# CTRL_MODULE_CORE_PAD register map
Vendor: Texas Instruments
Registers are 32-bit, access per field, reset 0x10F010F unless marked. A register's access mark holds for its fields unless they carry their own. Offsets are as the file gives them; [hi:lo] are bit positions; 'fields as' and 'values as' point back to an identical list.

## CTRL_MODULE_CORE_PAD (part 5 of 7)
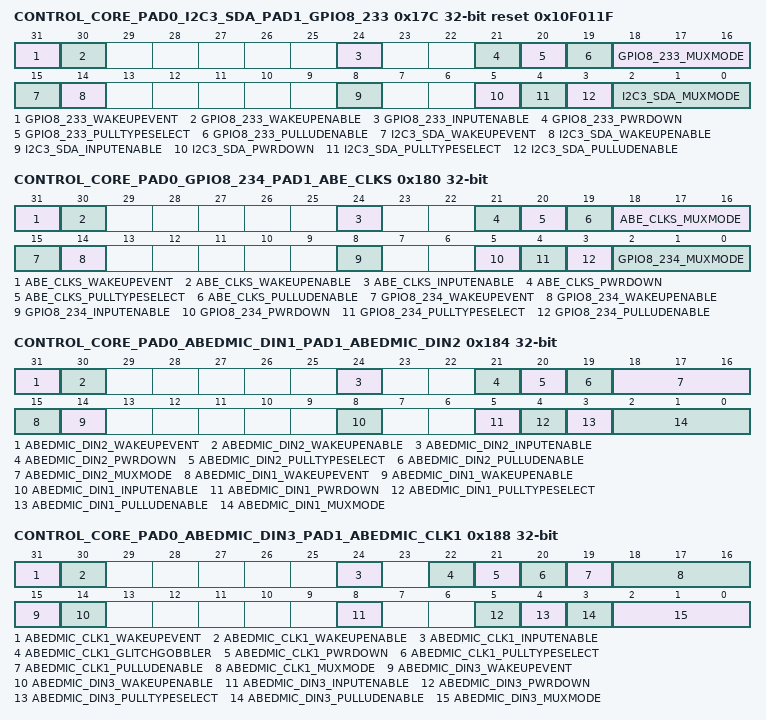
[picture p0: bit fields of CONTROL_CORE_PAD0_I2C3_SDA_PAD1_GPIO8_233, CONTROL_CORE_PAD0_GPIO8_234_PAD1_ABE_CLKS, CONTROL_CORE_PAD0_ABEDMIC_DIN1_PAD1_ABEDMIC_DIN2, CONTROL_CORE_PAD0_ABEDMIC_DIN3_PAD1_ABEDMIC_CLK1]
0x17C CONTROL_CORE_PAD0_I2C3_SDA_PAD1_GPIO8_233 reset 0x10F011F — Register control for Pads i2c3_sda and gpio8_233 Access conditions. Read: unrestricted, Write: unrestricted
  [31] GPIO8_233_WAKEUPEVENT ro — Pad_x wake-up event status latched in the IO
    1=WakeUp (A wake-up event occurred); 0=No wake-up event occurred
  [30] GPIO8_233_WAKEUPENABLE rw — Input pad wake-up enable
    0=DetectLow (wake-up detection is disabled); 1=DetectLowHigh (wake-up detection is enabled)
  [24] GPIO8_233_INPUTENABLE rw — Input enable value for pad gpio8_233
    0=InputBufferDisabled (Input buffer of IO cell is disabled); 1=InputBufferEnabled (Input buffer of IO cell is enabled)
  [21] GPIO8_233_PWRDOWN rw — Power Down setting for pad gpio8_233
    0=PwrDownDisabled (IO cell power is ON); 1=PwrDownEnabled (IO cell power is OFF)
  [20] GPIO8_233_PULLTYPESELECT rw — Pull-Up/Down selection for pad gpio8_233
    0=Pull-Down selected; 1=Pull-Up selected
  [19] GPIO8_233_PULLUDENABLE rw — Pull-Up/Down enable for pad gpio8_233
    0=PullDisabled (Pull-Up/Down disabled); 1=PullEnabled (Pull-Up/Down enabled)
  [18:16] GPIO8_233_MUXMODE rw — Functional multiplexing selection for pad gpio8_233
    6=SEL_GPIO8_233_1 (Select gpio8_233); 1=SEL_SYS_SECURE_INDICATOR (Reserved); 7=SEL_SAFE_MODE_CORE139 (Select safe_mode_core139); 0=SEL_GPIO8_233 (Select gpio8_233); 2=SEL_TIMER8_PWM_EVT (Select timer8_pwm_evt); 3=SEL_CPI_HSYNC (Select cpi_hsync)
  [15] I2C3_SDA_WAKEUPEVENT ro — Pad_x wake-up event status latched in the IO
    values as GPIO8_233_WAKEUPEVENT
  [14] I2C3_SDA_WAKEUPENABLE rw — Input pad wake-up enable
    values as GPIO8_233_WAKEUPENABLE
  [8] I2C3_SDA_INPUTENABLE rw — Input enable value for pad i2c3_sda
    values as GPIO8_233_INPUTENABLE
  [5] I2C3_SDA_PWRDOWN rw — Power Down setting for pad i2c3_sda
    values as GPIO8_233_PWRDOWN
  [4] I2C3_SDA_PULLTYPESELECT rw — Pull-Up/Down selection for pad i2c3_sda
    0=Pull-Down selected; 1=Pull-Up selected
  [3] I2C3_SDA_PULLUDENABLE rw — Pull-Up/Down enable for pad i2c3_sda
    values as GPIO8_233_PULLUDENABLE
  [2:0] I2C3_SDA_MUXMODE rw — Functional multiplexing selection for pad i2c3_sda
    0=SEL_I2C3_SDA (Select i2c3_sda); 7=SEL_SAFE_MODE_CORE138 (Select safe_mode_core138); 6=SEL_GPIO8_232 (Select gpio8_232)
0x180 CONTROL_CORE_PAD0_GPIO8_234_PAD1_ABE_CLKS — Register control for Pads gpio8_234 and abe_clks Access conditions. Read: unrestricted, Write: unrestricted
  [31] ABE_CLKS_WAKEUPEVENT ro — Pad_x wake-up event status latched in the IO
    values as CONTROL_CORE_PAD0_I2C3_SDA_PAD1_GPIO8_233.GPIO8_233_WAKEUPEVENT
  [30] ABE_CLKS_WAKEUPENABLE rw — Input pad wake-up enable
    values as CONTROL_CORE_PAD0_I2C3_SDA_PAD1_GPIO8_233.GPIO8_233_WAKEUPENABLE
  [24] ABE_CLKS_INPUTENABLE rw — Input enable value for pad abe_clks
    values as CONTROL_CORE_PAD0_I2C3_SDA_PAD1_GPIO8_233.GPIO8_233_INPUTENABLE
  [21] ABE_CLKS_PWRDOWN rw — Power Down setting for pad abe_clks
    values as CONTROL_CORE_PAD0_I2C3_SDA_PAD1_GPIO8_233.GPIO8_233_PWRDOWN
  [20] ABE_CLKS_PULLTYPESELECT rw — Pull-Up/Down selection for pad abe_clks
    0=Pull-Down selected; 1=Pull-Up selected
  [19] ABE_CLKS_PULLUDENABLE rw — Pull-Up/Down enable for pad abe_clks
    values as CONTROL_CORE_PAD0_I2C3_SDA_PAD1_GPIO8_233.GPIO8_233_PULLUDENABLE
  [18:16] ABE_CLKS_MUXMODE rw — Functional multiplexing selection for pad abe_clks
    0=SEL_ABE_CLKS (Select abe_clks); 3=SEL_ABEMCASP_AXR (Select abemcasp_axr); 7=SEL_SAFE_MODE_CORE141 (Select safe_mode_core141); 6=SEL_GPIO4_96 (Select gpio4_96)
  [15] GPIO8_234_WAKEUPEVENT ro — Pad_x wake-up event status latched in the IO
    values as CONTROL_CORE_PAD0_I2C3_SDA_PAD1_GPIO8_233.GPIO8_233_WAKEUPEVENT
  [14] GPIO8_234_WAKEUPENABLE rw — Input pad wake-up enable
    values as CONTROL_CORE_PAD0_I2C3_SDA_PAD1_GPIO8_233.GPIO8_233_WAKEUPENABLE
  [8] GPIO8_234_INPUTENABLE rw — Input enable value for pad gpio8_234
    values as CONTROL_CORE_PAD0_I2C3_SDA_PAD1_GPIO8_233.GPIO8_233_INPUTENABLE
  [5] GPIO8_234_PWRDOWN rw — Power Down setting for pad gpio8_234
    values as CONTROL_CORE_PAD0_I2C3_SDA_PAD1_GPIO8_233.GPIO8_233_PWRDOWN
  [4] GPIO8_234_PULLTYPESELECT rw — Pull-Up/Down selection for pad gpio8_234
    0=Pull-Down selected; 1=Pull-Up selected
  [3] GPIO8_234_PULLUDENABLE rw — Pull-Up/Down enable for pad gpio8_234
    values as CONTROL_CORE_PAD0_I2C3_SDA_PAD1_GPIO8_233.GPIO8_233_PULLUDENABLE
  [2:0] GPIO8_234_MUXMODE rw — Functional multiplexing selection for pad gpio8_234
    0=SEL_GPIO8_234 (Select gpio8_234); 1=SEL_SYS_DRM_MSECURE (Reserved); 3=SEL_CPI_VSYNC (Select cpi_vsync); 7=SEL_SAFE_MODE_CORE140 (Select safe_mode_core140); 6=SEL_GPIO8_234_1 (Select gpio8_234)
0x184 CONTROL_CORE_PAD0_ABEDMIC_DIN1_PAD1_ABEDMIC_DIN2 — Register control for Pads abedmic_din1 and abedmic_din2 Access conditions. Read: unrestricted, Write: unrestricted
  [31] ABEDMIC_DIN2_WAKEUPEVENT ro — Pad_x wake-up event status latched in the IO
    values as CONTROL_CORE_PAD0_I2C3_SDA_PAD1_GPIO8_233.GPIO8_233_WAKEUPEVENT
  [30] ABEDMIC_DIN2_WAKEUPENABLE rw — Input pad wake-up enable
    values as CONTROL_CORE_PAD0_I2C3_SDA_PAD1_GPIO8_233.GPIO8_233_WAKEUPENABLE
  [24] ABEDMIC_DIN2_INPUTENABLE rw — Input enable value for pad abedmic_din2
    values as CONTROL_CORE_PAD0_I2C3_SDA_PAD1_GPIO8_233.GPIO8_233_INPUTENABLE
  [21] ABEDMIC_DIN2_PWRDOWN rw — Power Down setting for pad abedmic_din2
    values as CONTROL_CORE_PAD0_I2C3_SDA_PAD1_GPIO8_233.GPIO8_233_PWRDOWN
  [20] ABEDMIC_DIN2_PULLTYPESELECT rw — Pull-Up/Down selection for pad abedmic_din2
    0=Pull-Down selected; 1=Pull-Up selected
  [19] ABEDMIC_DIN2_PULLUDENABLE rw — Pull-Up/Down enable for pad abedmic_din2
    values as CONTROL_CORE_PAD0_I2C3_SDA_PAD1_GPIO8_233.GPIO8_233_PULLUDENABLE
  [18:16] ABEDMIC_DIN2_MUXMODE rw — Functional multiplexing selection for pad abedmic_din2
    0=SEL_ABEDMIC_DIN2 (Select abedmic_din2); 3=SEL_ABEMCASP_AXR (Select abemcasp_axr); 4=SEL_ABEMCBSP3_DX (Select abemcbsp3_dx); 7=SEL_SAFE_MODE_CORE143 (Select safe_mode_core143); 6=SEL_GPIO4_98 (Select gpio4_98)
  [15] ABEDMIC_DIN1_WAKEUPEVENT ro — Pad_x wake-up event status latched in the IO
    values as CONTROL_CORE_PAD0_I2C3_SDA_PAD1_GPIO8_233.GPIO8_233_WAKEUPEVENT
  [14] ABEDMIC_DIN1_WAKEUPENABLE rw — Input pad wake-up enable
    values as CONTROL_CORE_PAD0_I2C3_SDA_PAD1_GPIO8_233.GPIO8_233_WAKEUPENABLE
  [8] ABEDMIC_DIN1_INPUTENABLE rw — Input enable value for pad abedmic_din1
    values as CONTROL_CORE_PAD0_I2C3_SDA_PAD1_GPIO8_233.GPIO8_233_INPUTENABLE
  [5] ABEDMIC_DIN1_PWRDOWN rw — Power Down setting for pad abedmic_din1
    values as CONTROL_CORE_PAD0_I2C3_SDA_PAD1_GPIO8_233.GPIO8_233_PWRDOWN
  [4] ABEDMIC_DIN1_PULLTYPESELECT rw — Pull-Up/Down selection for pad abedmic_din1
    0=Pull-Down selected; 1=Pull-Up selected
  [3] ABEDMIC_DIN1_PULLUDENABLE rw — Pull-Up/Down enable for pad abedmic_din1
    values as CONTROL_CORE_PAD0_I2C3_SDA_PAD1_GPIO8_233.GPIO8_233_PULLUDENABLE
  [2:0] ABEDMIC_DIN1_MUXMODE rw — Functional multiplexing selection for pad abedmic_din1
    0=SEL_ABEDMIC_DIN1 (Select abedmic_din1); 3=SEL_ABEMCASP_AHCLKR (Select abemcasp_ahclkr); 4=SEL_ABEMCBSP3_FSX (Select abemcbsp3_fsx); 7=SEL_SAFE_MODE_CORE142 (Select safe_mode_core142); 6=SEL_GPIO4_97 (Select gpio4_97)
0x188 CONTROL_CORE_PAD0_ABEDMIC_DIN3_PAD1_ABEDMIC_CLK1 — Register control for Pads abedmic_din3 and abedmic_clk1 Access conditions. Read: unrestricted, Write: unrestricted
  [31] ABEDMIC_CLK1_WAKEUPEVENT ro — Pad_x wake-up event status latched in the IO
    values as CONTROL_CORE_PAD0_I2C3_SDA_PAD1_GPIO8_233.GPIO8_233_WAKEUPEVENT
  [30] ABEDMIC_CLK1_WAKEUPENABLE rw — Input pad wake-up enable
    values as CONTROL_CORE_PAD0_I2C3_SDA_PAD1_GPIO8_233.GPIO8_233_WAKEUPENABLE
  [24] ABEDMIC_CLK1_INPUTENABLE rw — Input enable value for pad abedmic_clk1
    values as CONTROL_CORE_PAD0_I2C3_SDA_PAD1_GPIO8_233.GPIO8_233_INPUTENABLE
  [22] ABEDMIC_CLK1_GLITCHGOBBLER rw — Glitch Gobbler setting for pad abedmic_clk1
    0=GlitchGobblerDisabled (IO do not Filter glitch from outside); 1=GlitchGobblerEnabled (IO Filter glitch from outside)
  [21] ABEDMIC_CLK1_PWRDOWN rw — Power Down setting for pad abedmic_clk1
    values as CONTROL_CORE_PAD0_I2C3_SDA_PAD1_GPIO8_233.GPIO8_233_PWRDOWN
  [20] ABEDMIC_CLK1_PULLTYPESELECT rw — Pull-Up/Down selection for pad abedmic_clk1
    0=Pull-Down selected; 1=Pull-Up selected
  [19] ABEDMIC_CLK1_PULLUDENABLE rw — Pull-Up/Down enable for pad abedmic_clk1
    values as CONTROL_CORE_PAD0_I2C3_SDA_PAD1_GPIO8_233.GPIO8_233_PULLUDENABLE
  [18:16] ABEDMIC_CLK1_MUXMODE rw — Functional multiplexing selection for pad abedmic_clk1
    0=SEL_ABEDMIC_CLK1 (Select abedmic_clk1); 4=SEL_ABEMCBSP3_CLKX (Select abemcbsp3_clkx); 7=SEL_SAFE_MODE_CORE145 (Select safe_mode_core145); 6=SEL_GPIO4_100 (Select gpio4_100)
  [15] ABEDMIC_DIN3_WAKEUPEVENT ro — Pad_x wake-up event status latched in the IO
    values as CONTROL_CORE_PAD0_I2C3_SDA_PAD1_GPIO8_233.GPIO8_233_WAKEUPEVENT
  [14] ABEDMIC_DIN3_WAKEUPENABLE rw — Input pad wake-up enable
    values as CONTROL_CORE_PAD0_I2C3_SDA_PAD1_GPIO8_233.GPIO8_233_WAKEUPENABLE
  [8] ABEDMIC_DIN3_INPUTENABLE rw — Input enable value for pad abedmic_din3
    values as CONTROL_CORE_PAD0_I2C3_SDA_PAD1_GPIO8_233.GPIO8_233_INPUTENABLE
  [5] ABEDMIC_DIN3_PWRDOWN rw — Power Down setting for pad abedmic_din3
    values as CONTROL_CORE_PAD0_I2C3_SDA_PAD1_GPIO8_233.GPIO8_233_PWRDOWN
  [4] ABEDMIC_DIN3_PULLTYPESELECT rw — Pull-Up/Down selection for pad abedmic_din3
    0=Pull-Down selected; 1=Pull-Up selected
  [3] ABEDMIC_DIN3_PULLUDENABLE rw — Pull-Up/Down enable for pad abedmic_din3
    values as CONTROL_CORE_PAD0_I2C3_SDA_PAD1_GPIO8_233.GPIO8_233_PULLUDENABLE
  [2:0] ABEDMIC_DIN3_MUXMODE rw — Functional multiplexing selection for pad abedmic_din3
    0=SEL_ABEDMIC_DIN3 (Select abedmic_din3); 4=SEL_ABEMCBSP3_DR (Select abemcbsp3_dr); 7=SEL_SAFE_MODE_CORE144 (Select safe_mode_core144); 6=SEL_GPIO4_99 (Select gpio4_99)
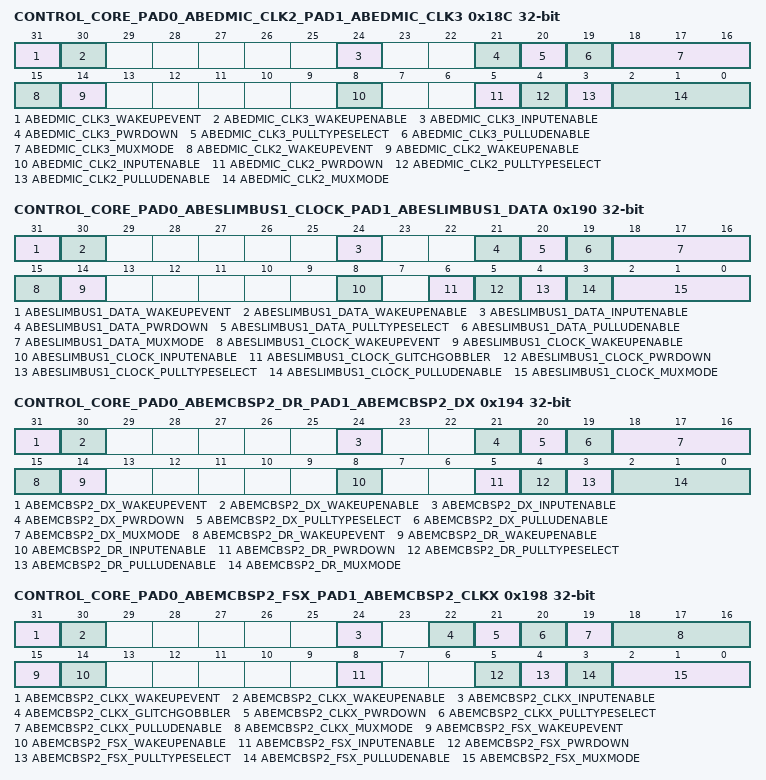
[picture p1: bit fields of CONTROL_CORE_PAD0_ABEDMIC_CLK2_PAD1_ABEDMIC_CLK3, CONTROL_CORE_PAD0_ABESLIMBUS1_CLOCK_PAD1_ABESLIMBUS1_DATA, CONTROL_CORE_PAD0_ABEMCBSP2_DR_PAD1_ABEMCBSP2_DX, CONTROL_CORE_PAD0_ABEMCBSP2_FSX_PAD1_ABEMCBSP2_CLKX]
0x18C CONTROL_CORE_PAD0_ABEDMIC_CLK2_PAD1_ABEDMIC_CLK3 — Register control for Pads abedmic_clk2 and abedmic_clk3 Access conditions. Read: unrestricted, Write: unrestricted
  [31] ABEDMIC_CLK3_WAKEUPEVENT ro — Pad_x wake-up event status latched in the IO
    values as CONTROL_CORE_PAD0_I2C3_SDA_PAD1_GPIO8_233.GPIO8_233_WAKEUPEVENT
  [30] ABEDMIC_CLK3_WAKEUPENABLE rw — Input pad wake-up enable
    values as CONTROL_CORE_PAD0_I2C3_SDA_PAD1_GPIO8_233.GPIO8_233_WAKEUPENABLE
  [24] ABEDMIC_CLK3_INPUTENABLE rw — Input enable value for pad abedmic_clk3
    values as CONTROL_CORE_PAD0_I2C3_SDA_PAD1_GPIO8_233.GPIO8_233_INPUTENABLE
  [21] ABEDMIC_CLK3_PWRDOWN rw — Power Down setting for pad abedmic_clk3
    values as CONTROL_CORE_PAD0_I2C3_SDA_PAD1_GPIO8_233.GPIO8_233_PWRDOWN
  [20] ABEDMIC_CLK3_PULLTYPESELECT rw — Pull-Up/Down selection for pad abedmic_clk3
    0=Pull-Down selected; 1=Pull-Up selected
  [19] ABEDMIC_CLK3_PULLUDENABLE rw — Pull-Up/Down enable for pad abedmic_clk3
    values as CONTROL_CORE_PAD0_I2C3_SDA_PAD1_GPIO8_233.GPIO8_233_PULLUDENABLE
  [18:16] ABEDMIC_CLK3_MUXMODE rw — Functional multiplexing selection for pad abedmic_clk3
    0=SEL_ABEDMIC_CLK3 (Select abedmic_clk3); 1=SEL_ABEMCBSP1_DX (Select abemcbsp1_dx); 3=SEL_ABEMCASP_ACLKX (Select abemcasp_aclkx); 7=SEL_SAFE_MODE_CORE147 (Select safe_mode_core147); 6=SEL_GPIO4_102 (Select gpio4_102)
  [15] ABEDMIC_CLK2_WAKEUPEVENT ro — Pad_x wake-up event status latched in the IO
    values as CONTROL_CORE_PAD0_I2C3_SDA_PAD1_GPIO8_233.GPIO8_233_WAKEUPEVENT
  [14] ABEDMIC_CLK2_WAKEUPENABLE rw — Input pad wake-up enable
    values as CONTROL_CORE_PAD0_I2C3_SDA_PAD1_GPIO8_233.GPIO8_233_WAKEUPENABLE
  [8] ABEDMIC_CLK2_INPUTENABLE rw — Input enable value for pad abedmic_clk2
    values as CONTROL_CORE_PAD0_I2C3_SDA_PAD1_GPIO8_233.GPIO8_233_INPUTENABLE
  [5] ABEDMIC_CLK2_PWRDOWN rw — Power Down setting for pad abedmic_clk2
    values as CONTROL_CORE_PAD0_I2C3_SDA_PAD1_GPIO8_233.GPIO8_233_PWRDOWN
  [4] ABEDMIC_CLK2_PULLTYPESELECT rw — Pull-Up/Down selection for pad abedmic_clk2
    0=Pull-Down selected; 1=Pull-Up selected
  [3] ABEDMIC_CLK2_PULLUDENABLE rw — Pull-Up/Down enable for pad abedmic_clk2
    values as CONTROL_CORE_PAD0_I2C3_SDA_PAD1_GPIO8_233.GPIO8_233_PULLUDENABLE
  [2:0] ABEDMIC_CLK2_MUXMODE rw — Functional multiplexing selection for pad abedmic_clk2
    0=SEL_ABEDMIC_CLK2 (Select abedmic_clk2); 1=SEL_ABEMCBSP1_FSX (Select abemcbsp1_fsx); 3=SEL_ABEMCASP_AMUTEIN (Select abemcasp_amutein); 7=SEL_SAFE_MODE_CORE146 (Select safe_mode_core146); 6=SEL_GPIO4_101 (Select gpio4_101)
0x190 CONTROL_CORE_PAD0_ABESLIMBUS1_CLOCK_PAD1_ABESLIMBUS1_DATA — Register control for Pads abeslimbus1_clock and abeslimbus1_data Access conditions. Read: unrestricted, Write: unrestricted
  [31] ABESLIMBUS1_DATA_WAKEUPEVENT ro — Pad_x wake-up event status latched in the IO
    values as CONTROL_CORE_PAD0_I2C3_SDA_PAD1_GPIO8_233.GPIO8_233_WAKEUPEVENT
  [30] ABESLIMBUS1_DATA_WAKEUPENABLE rw — Input pad wake-up enable
    values as CONTROL_CORE_PAD0_I2C3_SDA_PAD1_GPIO8_233.GPIO8_233_WAKEUPENABLE
  [24] ABESLIMBUS1_DATA_INPUTENABLE rw — Input enable value for pad abeslimbus1_data
    values as CONTROL_CORE_PAD0_I2C3_SDA_PAD1_GPIO8_233.GPIO8_233_INPUTENABLE
  [21] ABESLIMBUS1_DATA_PWRDOWN rw — Power Down setting for pad abeslimbus1_data
    values as CONTROL_CORE_PAD0_I2C3_SDA_PAD1_GPIO8_233.GPIO8_233_PWRDOWN
  [20] ABESLIMBUS1_DATA_PULLTYPESELECT rw — Pull-Up/Down selection for pad abeslimbus1_data
    0=Pull-Down selected; 1=Pull-Up selected
  [19] ABESLIMBUS1_DATA_PULLUDENABLE rw — Pull-Up/Down enable for pad abeslimbus1_data
    values as CONTROL_CORE_PAD0_I2C3_SDA_PAD1_GPIO8_233.GPIO8_233_PULLUDENABLE
  [18:16] ABESLIMBUS1_DATA_MUXMODE rw — Functional multiplexing selection for pad abeslimbus1_data
    0=SEL_ABESLIMBUS1_DATA (Select abeslimbus1_data); 1=SEL_ABEMCBSP1_DR (Select abemcbsp1_dr); 3=SEL_ABEMCASP_ACLKR (Select abemcasp_aclkr); 7=SEL_SAFE_MODE_CORE149 (Select safe_mode_core149); 6=SEL_GPIO4_104 (Select gpio4_104)
  [15] ABESLIMBUS1_CLOCK_WAKEUPEVENT ro — Pad_x wake-up event status latched in the IO
    values as CONTROL_CORE_PAD0_I2C3_SDA_PAD1_GPIO8_233.GPIO8_233_WAKEUPEVENT
  [14] ABESLIMBUS1_CLOCK_WAKEUPENABLE rw — Input pad wake-up enable
    values as CONTROL_CORE_PAD0_I2C3_SDA_PAD1_GPIO8_233.GPIO8_233_WAKEUPENABLE
  [8] ABESLIMBUS1_CLOCK_INPUTENABLE rw — Input enable value for pad abeslimbus1_clock
    values as CONTROL_CORE_PAD0_I2C3_SDA_PAD1_GPIO8_233.GPIO8_233_INPUTENABLE
  [6] ABESLIMBUS1_CLOCK_GLITCHGOBBLER rw — Glitch Gobbler setting for pad abeslimbus1_clock
    values as CONTROL_CORE_PAD0_ABEDMIC_DIN3_PAD1_ABEDMIC_CLK1.ABEDMIC_CLK1_GLITCHGOBBLER
  [5] ABESLIMBUS1_CLOCK_PWRDOWN rw — Power Down setting for pad abeslimbus1_clock
    values as CONTROL_CORE_PAD0_I2C3_SDA_PAD1_GPIO8_233.GPIO8_233_PWRDOWN
  [4] ABESLIMBUS1_CLOCK_PULLTYPESELECT rw — Pull-Up/Down selection for pad abeslimbus1_clock
    0=Pull-Down selected; 1=Pull-Up selected
  [3] ABESLIMBUS1_CLOCK_PULLUDENABLE rw — Pull-Up/Down enable for pad abeslimbus1_clock
    values as CONTROL_CORE_PAD0_I2C3_SDA_PAD1_GPIO8_233.GPIO8_233_PULLUDENABLE
  [2:0] ABESLIMBUS1_CLOCK_MUXMODE rw — Functional multiplexing selection for pad abeslimbus1_clock
    0=SEL_ABESLIMBUS1_CLOCK (Select abeslimbus1_clock); 1=SEL_ABEMCBSP1_CLKX (Select abemcbsp1_clkx); 3=SEL_ABEMCASP_AFSR (Select abemcasp_afsr); 7=SEL_SAFE_MODE_CORE148 (Select safe_mode_core148); 6=SEL_GPIO4_103 (Select gpio4_103)
0x194 CONTROL_CORE_PAD0_ABEMCBSP2_DR_PAD1_ABEMCBSP2_DX — Register control for Pads abemcbsp2_dr and abemcbsp2_dx Access conditions. Read: unrestricted, Write: unrestricted
  [31] ABEMCBSP2_DX_WAKEUPEVENT ro — Pad_x wake-up event status latched in the IO
    values as CONTROL_CORE_PAD0_I2C3_SDA_PAD1_GPIO8_233.GPIO8_233_WAKEUPEVENT
  [30] ABEMCBSP2_DX_WAKEUPENABLE rw — Input pad wake-up enable
    values as CONTROL_CORE_PAD0_I2C3_SDA_PAD1_GPIO8_233.GPIO8_233_WAKEUPENABLE
  [24] ABEMCBSP2_DX_INPUTENABLE rw — Input enable value for pad abemcbsp2_dx
    values as CONTROL_CORE_PAD0_I2C3_SDA_PAD1_GPIO8_233.GPIO8_233_INPUTENABLE
  [21] ABEMCBSP2_DX_PWRDOWN rw — Power Down setting for pad abemcbsp2_dx
    values as CONTROL_CORE_PAD0_I2C3_SDA_PAD1_GPIO8_233.GPIO8_233_PWRDOWN
  [20] ABEMCBSP2_DX_PULLTYPESELECT rw — Pull-Up/Down selection for pad abemcbsp2_dx
    0=Pull-Down selected; 1=Pull-Up selected
  [19] ABEMCBSP2_DX_PULLUDENABLE rw — Pull-Up/Down enable for pad abemcbsp2_dx
    values as CONTROL_CORE_PAD0_I2C3_SDA_PAD1_GPIO8_233.GPIO8_233_PULLUDENABLE
  [18:16] ABEMCBSP2_DX_MUXMODE rw — Functional multiplexing selection for pad abemcbsp2_dx
    0=SEL_ABEMCBSP2_DX (Select abemcbsp2_dx); 3=SEL_ABEMCASP_AMUTEOUT (Select abemcasp_amuteout); 7=SEL_SAFE_MODE_CORE151 (Select safe_mode_core151); 6=SEL_GPIO4_106 (Select gpio4_106)
  [15] ABEMCBSP2_DR_WAKEUPEVENT ro — Pad_x wake-up event status latched in the IO
    values as CONTROL_CORE_PAD0_I2C3_SDA_PAD1_GPIO8_233.GPIO8_233_WAKEUPEVENT
  [14] ABEMCBSP2_DR_WAKEUPENABLE rw — Input pad wake-up enable
    values as CONTROL_CORE_PAD0_I2C3_SDA_PAD1_GPIO8_233.GPIO8_233_WAKEUPENABLE
  [8] ABEMCBSP2_DR_INPUTENABLE rw — Input enable value for pad abemcbsp2_dr
    values as CONTROL_CORE_PAD0_I2C3_SDA_PAD1_GPIO8_233.GPIO8_233_INPUTENABLE
  [5] ABEMCBSP2_DR_PWRDOWN rw — Power Down setting for pad abemcbsp2_dr
    values as CONTROL_CORE_PAD0_I2C3_SDA_PAD1_GPIO8_233.GPIO8_233_PWRDOWN
  [4] ABEMCBSP2_DR_PULLTYPESELECT rw — Pull-Up/Down selection for pad abemcbsp2_dr
    0=Pull-Down selected; 1=Pull-Up selected
  [3] ABEMCBSP2_DR_PULLUDENABLE rw — Pull-Up/Down enable for pad abemcbsp2_dr
    values as CONTROL_CORE_PAD0_I2C3_SDA_PAD1_GPIO8_233.GPIO8_233_PULLUDENABLE
  [2:0] ABEMCBSP2_DR_MUXMODE rw — Functional multiplexing selection for pad abemcbsp2_dr
    0=SEL_ABEMCBSP2_DR (Select abemcbsp2_dr); 3=SEL_ABEMCASP_AXR (Select abemcasp_axr); 7=SEL_SAFE_MODE_CORE150 (Select safe_mode_core150); 6=SEL_GPIO4_105 (Select gpio4_105)
0x198 CONTROL_CORE_PAD0_ABEMCBSP2_FSX_PAD1_ABEMCBSP2_CLKX — Register control for Pads abemcbsp2_fsx and abemcbsp2_clkx Access conditions. Read: unrestricted, Write: unrestricted
  [31] ABEMCBSP2_CLKX_WAKEUPEVENT ro — Pad_x wake-up event status latched in the IO
    values as CONTROL_CORE_PAD0_I2C3_SDA_PAD1_GPIO8_233.GPIO8_233_WAKEUPEVENT
  [30] ABEMCBSP2_CLKX_WAKEUPENABLE rw — Input pad wake-up enable
    values as CONTROL_CORE_PAD0_I2C3_SDA_PAD1_GPIO8_233.GPIO8_233_WAKEUPENABLE
  [24] ABEMCBSP2_CLKX_INPUTENABLE rw — Input enable value for pad abemcbsp2_clkx
    values as CONTROL_CORE_PAD0_I2C3_SDA_PAD1_GPIO8_233.GPIO8_233_INPUTENABLE
  [22] ABEMCBSP2_CLKX_GLITCHGOBBLER rw — Glitch Gobbler setting for pad abemcbsp2_clkx
    values as CONTROL_CORE_PAD0_ABEDMIC_DIN3_PAD1_ABEDMIC_CLK1.ABEDMIC_CLK1_GLITCHGOBBLER
  [21] ABEMCBSP2_CLKX_PWRDOWN rw — Power Down setting for pad abemcbsp2_clkx
    values as CONTROL_CORE_PAD0_I2C3_SDA_PAD1_GPIO8_233.GPIO8_233_PWRDOWN
  [20] ABEMCBSP2_CLKX_PULLTYPESELECT rw — Pull-Up/Down selection for pad abemcbsp2_clkx
    0=Pull-Down selected; 1=Pull-Up selected
  [19] ABEMCBSP2_CLKX_PULLUDENABLE rw — Pull-Up/Down enable for pad abemcbsp2_clkx
    values as CONTROL_CORE_PAD0_I2C3_SDA_PAD1_GPIO8_233.GPIO8_233_PULLUDENABLE
  [18:16] ABEMCBSP2_CLKX_MUXMODE rw — Functional multiplexing selection for pad abemcbsp2_clkx
    0=SEL_ABEMCBSP2_CLKX (Select abemcbsp2_clkx); 3=SEL_ABEMCASP_AHCLKX (Select abemcasp_ahclkx); 7=SEL_SAFE_MODE_CORE153 (Select safe_mode_core153); 6=SEL_GPIO4_108 (Select gpio4_108)
  [15] ABEMCBSP2_FSX_WAKEUPEVENT ro — Pad_x wake-up event status latched in the IO
    values as CONTROL_CORE_PAD0_I2C3_SDA_PAD1_GPIO8_233.GPIO8_233_WAKEUPEVENT
  [14] ABEMCBSP2_FSX_WAKEUPENABLE rw — Input pad wake-up enable
    values as CONTROL_CORE_PAD0_I2C3_SDA_PAD1_GPIO8_233.GPIO8_233_WAKEUPENABLE
  [8] ABEMCBSP2_FSX_INPUTENABLE rw — Input enable value for pad abemcbsp2_fsx
    values as CONTROL_CORE_PAD0_I2C3_SDA_PAD1_GPIO8_233.GPIO8_233_INPUTENABLE
  [5] ABEMCBSP2_FSX_PWRDOWN rw — Power Down setting for pad abemcbsp2_fsx
    values as CONTROL_CORE_PAD0_I2C3_SDA_PAD1_GPIO8_233.GPIO8_233_PWRDOWN
  [4] ABEMCBSP2_FSX_PULLTYPESELECT rw — Pull-Up/Down selection for pad abemcbsp2_fsx
    0=Pull-Down selected; 1=Pull-Up selected
  [3] ABEMCBSP2_FSX_PULLUDENABLE rw — Pull-Up/Down enable for pad abemcbsp2_fsx
    values as CONTROL_CORE_PAD0_I2C3_SDA_PAD1_GPIO8_233.GPIO8_233_PULLUDENABLE
  [2:0] ABEMCBSP2_FSX_MUXMODE rw — Functional multiplexing selection for pad abemcbsp2_fsx
    0=SEL_ABEMCBSP2_FSX (Select abemcbsp2_fsx); 3=SEL_ABEMCASP_AFSX (Select abemcasp_afsx); 7=SEL_SAFE_MODE_CORE152 (Select safe_mode_core152); 6=SEL_GPIO4_107 (Select gpio4_107)
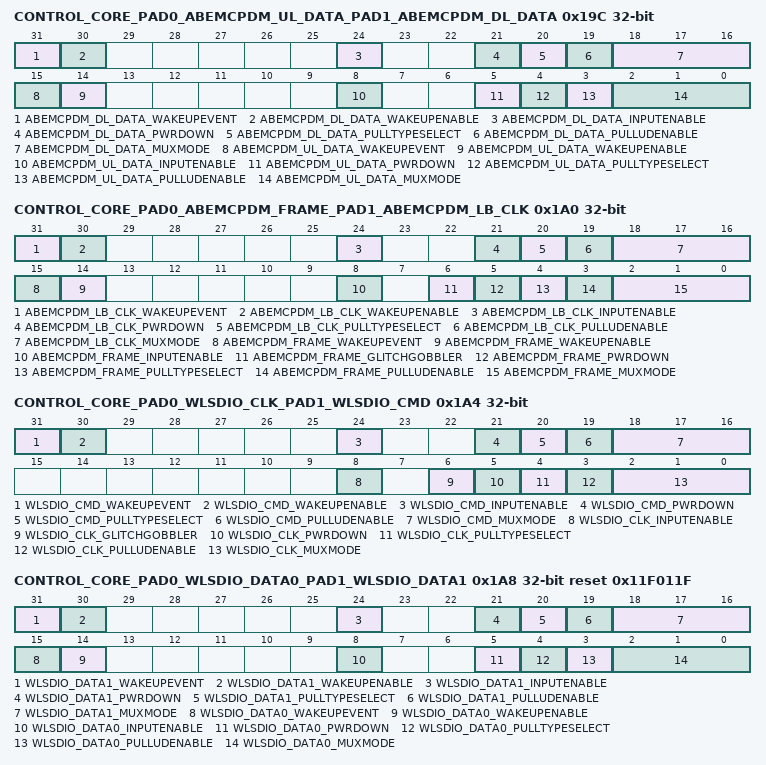
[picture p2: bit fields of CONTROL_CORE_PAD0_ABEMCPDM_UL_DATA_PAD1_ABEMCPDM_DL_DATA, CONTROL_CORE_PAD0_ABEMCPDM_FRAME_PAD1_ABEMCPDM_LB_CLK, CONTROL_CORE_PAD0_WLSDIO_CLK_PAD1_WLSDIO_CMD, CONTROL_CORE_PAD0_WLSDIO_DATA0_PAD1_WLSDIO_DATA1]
0x19C CONTROL_CORE_PAD0_ABEMCPDM_UL_DATA_PAD1_ABEMCPDM_DL_DATA — Register control for Pads abemcpdm_ul_data and abemcpdm_dl_data Access conditions. Read: unrestricted, Write: unrestricted
  [31] ABEMCPDM_DL_DATA_WAKEUPEVENT ro — Pad_x wake-up event status latched in the IO
    values as CONTROL_CORE_PAD0_I2C3_SDA_PAD1_GPIO8_233.GPIO8_233_WAKEUPEVENT
  [30] ABEMCPDM_DL_DATA_WAKEUPENABLE rw — Input pad wake-up enable
    values as CONTROL_CORE_PAD0_I2C3_SDA_PAD1_GPIO8_233.GPIO8_233_WAKEUPENABLE
  [24] ABEMCPDM_DL_DATA_INPUTENABLE rw — Input enable value for pad abemcpdm_dl_data
    values as CONTROL_CORE_PAD0_I2C3_SDA_PAD1_GPIO8_233.GPIO8_233_INPUTENABLE
  [21] ABEMCPDM_DL_DATA_PWRDOWN rw — Power Down setting for pad abemcpdm_dl_data
    values as CONTROL_CORE_PAD0_I2C3_SDA_PAD1_GPIO8_233.GPIO8_233_PWRDOWN
  [20] ABEMCPDM_DL_DATA_PULLTYPESELECT rw — Pull-Up/Down selection for pad abemcpdm_dl_data
    0=Pull-Down selected; 1=Pull-Up selected
  [19] ABEMCPDM_DL_DATA_PULLUDENABLE rw — Pull-Up/Down enable for pad abemcpdm_dl_data
    values as CONTROL_CORE_PAD0_I2C3_SDA_PAD1_GPIO8_233.GPIO8_233_PULLUDENABLE
  [18:16] ABEMCPDM_DL_DATA_MUXMODE rw — Functional multiplexing selection for pad abemcpdm_dl_data
    0=SEL_ABEMCPDM_DL_DATA (Select abemcpdm_dl_data); 1=SEL_ABEMCBSP3_DX (Select abemcbsp3_dx); 3=SEL_ABEMCASP_AXR2 (Select abemcasp_axr2); 7=SEL_SAFE_MODE_CORE155 (Select safe_mode_core155); 6=SEL_GPIO4_110 (Select gpio4_110)
  [15] ABEMCPDM_UL_DATA_WAKEUPEVENT ro — Pad_x wake-up event status latched in the IO
    values as CONTROL_CORE_PAD0_I2C3_SDA_PAD1_GPIO8_233.GPIO8_233_WAKEUPEVENT
  [14] ABEMCPDM_UL_DATA_WAKEUPENABLE rw — Input pad wake-up enable
    values as CONTROL_CORE_PAD0_I2C3_SDA_PAD1_GPIO8_233.GPIO8_233_WAKEUPENABLE
  [8] ABEMCPDM_UL_DATA_INPUTENABLE rw — Input enable value for pad abemcpdm_ul_data
    values as CONTROL_CORE_PAD0_I2C3_SDA_PAD1_GPIO8_233.GPIO8_233_INPUTENABLE
  [5] ABEMCPDM_UL_DATA_PWRDOWN rw — Power Down setting for pad abemcpdm_ul_data
    values as CONTROL_CORE_PAD0_I2C3_SDA_PAD1_GPIO8_233.GPIO8_233_PWRDOWN
  [4] ABEMCPDM_UL_DATA_PULLTYPESELECT rw — Pull-Up/Down selection for pad abemcpdm_ul_data
    0=Pull-Down selected; 1=Pull-Up selected
  [3] ABEMCPDM_UL_DATA_PULLUDENABLE rw — Pull-Up/Down enable for pad abemcpdm_ul_data
    values as CONTROL_CORE_PAD0_I2C3_SDA_PAD1_GPIO8_233.GPIO8_233_PULLUDENABLE
  [2:0] ABEMCPDM_UL_DATA_MUXMODE rw — Functional multiplexing selection for pad abemcpdm_ul_data
    0=SEL_ABEMCPDM_UL_DATA (Select abemcpdm_ul_data); 1=SEL_ABEMCBSP3_DR (Select abemcbsp3_dr); 3=SEL_ABEMCASP_AXR3 (Select abemcasp_axr3); 7=SEL_SAFE_MODE_CORE154 (Select safe_mode_core154); 6=SEL_GPIO4_109 (Select gpio4_109)
0x1A0 CONTROL_CORE_PAD0_ABEMCPDM_FRAME_PAD1_ABEMCPDM_LB_CLK — Register control for Pads abemcpdm_frame and abemcpdm_lb_clk Access conditions. Read: unrestricted, Write: unrestricted
  [31] ABEMCPDM_LB_CLK_WAKEUPEVENT ro — Pad_x wake-up event status latched in the IO
    values as CONTROL_CORE_PAD0_I2C3_SDA_PAD1_GPIO8_233.GPIO8_233_WAKEUPEVENT
  [30] ABEMCPDM_LB_CLK_WAKEUPENABLE rw — Input pad wake-up enable
    values as CONTROL_CORE_PAD0_I2C3_SDA_PAD1_GPIO8_233.GPIO8_233_WAKEUPENABLE
  [24] ABEMCPDM_LB_CLK_INPUTENABLE rw — Input enable value for pad abemcpdm_lb_clk
    values as CONTROL_CORE_PAD0_I2C3_SDA_PAD1_GPIO8_233.GPIO8_233_INPUTENABLE
  [21] ABEMCPDM_LB_CLK_PWRDOWN rw — Power Down setting for pad abemcpdm_lb_clk
    values as CONTROL_CORE_PAD0_I2C3_SDA_PAD1_GPIO8_233.GPIO8_233_PWRDOWN
  [20] ABEMCPDM_LB_CLK_PULLTYPESELECT rw — Pull-Up/Down selection for pad abemcpdm_lb_clk
    0=Pull-Down selected; 1=Pull-Up selected
  [19] ABEMCPDM_LB_CLK_PULLUDENABLE rw — Pull-Up/Down enable for pad abemcpdm_lb_clk
    values as CONTROL_CORE_PAD0_I2C3_SDA_PAD1_GPIO8_233.GPIO8_233_PULLUDENABLE
  [18:16] ABEMCPDM_LB_CLK_MUXMODE rw — Functional multiplexing selection for pad abemcpdm_lb_clk
    0=SEL_ABEMCPDM_LB_CLK (Select abemcpdm_lb_clk); 1=SEL_ABEMCBSP3_FSX (Select abemcbsp3_fsx); 7=SEL_SAFE_MODE_CORE157 (Select safe_mode_core157); 6=SEL_GPIO4_112 (Select gpio4_112)
  [15] ABEMCPDM_FRAME_WAKEUPEVENT ro — Pad_x wake-up event status latched in the IO
    values as CONTROL_CORE_PAD0_I2C3_SDA_PAD1_GPIO8_233.GPIO8_233_WAKEUPEVENT
  [14] ABEMCPDM_FRAME_WAKEUPENABLE rw — Input pad wake-up enable
    values as CONTROL_CORE_PAD0_I2C3_SDA_PAD1_GPIO8_233.GPIO8_233_WAKEUPENABLE
  [8] ABEMCPDM_FRAME_INPUTENABLE rw — Input enable value for pad abemcpdm_frame
    values as CONTROL_CORE_PAD0_I2C3_SDA_PAD1_GPIO8_233.GPIO8_233_INPUTENABLE
  [6] ABEMCPDM_FRAME_GLITCHGOBBLER rw — Glitch Gobbler setting for pad abemcpdm_frame
    values as CONTROL_CORE_PAD0_ABEDMIC_DIN3_PAD1_ABEDMIC_CLK1.ABEDMIC_CLK1_GLITCHGOBBLER
  [5] ABEMCPDM_FRAME_PWRDOWN rw — Power Down setting for pad abemcpdm_frame
    values as CONTROL_CORE_PAD0_I2C3_SDA_PAD1_GPIO8_233.GPIO8_233_PWRDOWN
  [4] ABEMCPDM_FRAME_PULLTYPESELECT rw — Pull-Up/Down selection for pad abemcpdm_frame
    0=Pull-Down selected; 1=Pull-Up selected
  [3] ABEMCPDM_FRAME_PULLUDENABLE rw — Pull-Up/Down enable for pad abemcpdm_frame
    values as CONTROL_CORE_PAD0_I2C3_SDA_PAD1_GPIO8_233.GPIO8_233_PULLUDENABLE
  [2:0] ABEMCPDM_FRAME_MUXMODE rw — Functional multiplexing selection for pad abemcpdm_frame
    0=SEL_ABEMCPDM_FRAME (Select abemcpdm_frame); 1=SEL_ABEMCBSP3_CLKX (Select abemcbsp3_clkx); 3=SEL_ABEMCASP_AXR1 (Select abemcasp_axr1); 7=SEL_SAFE_MODE_CORE156 (Select safe_mode_core156); 6=SEL_GPIO4_111 (Select gpio4_111)
0x1A4 CONTROL_CORE_PAD0_WLSDIO_CLK_PAD1_WLSDIO_CMD — Register control for Pads wlsdio_clk and wlsdio_cmd Access conditions. Read: unrestricted, Write: unrestricted
  [31] WLSDIO_CMD_WAKEUPEVENT ro — Pad_x wake-up event status latched in the IO
    values as CONTROL_CORE_PAD0_I2C3_SDA_PAD1_GPIO8_233.GPIO8_233_WAKEUPEVENT
  [30] WLSDIO_CMD_WAKEUPENABLE rw — Input pad wake-up enable
    values as CONTROL_CORE_PAD0_I2C3_SDA_PAD1_GPIO8_233.GPIO8_233_WAKEUPENABLE
  [24] WLSDIO_CMD_INPUTENABLE rw — Input enable value for pad wlsdio_cmd
    values as CONTROL_CORE_PAD0_I2C3_SDA_PAD1_GPIO8_233.GPIO8_233_INPUTENABLE
  [21] WLSDIO_CMD_PWRDOWN rw — Power Down setting for pad wlsdio_cmd
    values as CONTROL_CORE_PAD0_I2C3_SDA_PAD1_GPIO8_233.GPIO8_233_PWRDOWN
  [20] WLSDIO_CMD_PULLTYPESELECT rw — Pull-Up/Down selection for pad wlsdio_cmd
    0=Pull-Down selected; 1=Pull-Up selected
  [19] WLSDIO_CMD_PULLUDENABLE rw — Pull-Up/Down enable for pad wlsdio_cmd
    values as CONTROL_CORE_PAD0_I2C3_SDA_PAD1_GPIO8_233.GPIO8_233_PULLUDENABLE
  [18:16] WLSDIO_CMD_MUXMODE rw — Functional multiplexing selection for pad wlsdio_cmd
    0=SEL_WLSDIO_CMD (Select wlsdio_cmd); 7=SEL_SAFE_MODE_CORE159 (Select safe_mode_core159); 6=SEL_GPIO5_129 (Select gpio5_129)
  [8] WLSDIO_CLK_INPUTENABLE rw — Input enable value for pad wlsdio_clk
    values as CONTROL_CORE_PAD0_I2C3_SDA_PAD1_GPIO8_233.GPIO8_233_INPUTENABLE
  [6] WLSDIO_CLK_GLITCHGOBBLER rw — Glitch Gobbler setting for pad wlsdio_clk
    values as CONTROL_CORE_PAD0_ABEDMIC_DIN3_PAD1_ABEDMIC_CLK1.ABEDMIC_CLK1_GLITCHGOBBLER
  [5] WLSDIO_CLK_PWRDOWN rw — Power Down setting for pad wlsdio_clk
    values as CONTROL_CORE_PAD0_I2C3_SDA_PAD1_GPIO8_233.GPIO8_233_PWRDOWN
  [4] WLSDIO_CLK_PULLTYPESELECT rw — Pull-Up/Down selection for pad wlsdio_clk
    0=Pull-Down selected; 1=Pull-Up selected
  [3] WLSDIO_CLK_PULLUDENABLE rw — Pull-Up/Down enable for pad wlsdio_clk
    values as CONTROL_CORE_PAD0_I2C3_SDA_PAD1_GPIO8_233.GPIO8_233_PULLUDENABLE
  [2:0] WLSDIO_CLK_MUXMODE rw — Functional multiplexing selection for pad wlsdio_clk
    0=SEL_WLSDIO_CLK (Select wlsdio_clk); 1=SEL_MCSPI4_CLK (Select mcspi4_clk); 7=SEL_SAFE_MODE_CORE158 (Select safe_mode_core158); 6=SEL_GPIO5_128 (Select gpio5_128)
0x1A8 CONTROL_CORE_PAD0_WLSDIO_DATA0_PAD1_WLSDIO_DATA1 reset 0x11F011F — Register control for Pads wlsdio_data0 and wlsdio_data1 Access conditions. Read: unrestricted, Write: unrestricted
  [31] WLSDIO_DATA1_WAKEUPEVENT ro — Pad_x wake-up event status latched in the IO
    values as CONTROL_CORE_PAD0_I2C3_SDA_PAD1_GPIO8_233.GPIO8_233_WAKEUPEVENT
  [30] WLSDIO_DATA1_WAKEUPENABLE rw — Input pad wake-up enable
    values as CONTROL_CORE_PAD0_I2C3_SDA_PAD1_GPIO8_233.GPIO8_233_WAKEUPENABLE
  [24] WLSDIO_DATA1_INPUTENABLE rw — Input enable value for pad wlsdio_data1
    values as CONTROL_CORE_PAD0_I2C3_SDA_PAD1_GPIO8_233.GPIO8_233_INPUTENABLE
  [21] WLSDIO_DATA1_PWRDOWN rw — Power Down setting for pad wlsdio_data1
    values as CONTROL_CORE_PAD0_I2C3_SDA_PAD1_GPIO8_233.GPIO8_233_PWRDOWN
  [20] WLSDIO_DATA1_PULLTYPESELECT rw — Pull-Up/Down selection for pad wlsdio_data1
    0=Pull-Down selected; 1=Pull-Up selected
  [19] WLSDIO_DATA1_PULLUDENABLE rw — Pull-Up/Down enable for pad wlsdio_data1
    values as CONTROL_CORE_PAD0_I2C3_SDA_PAD1_GPIO8_233.GPIO8_233_PULLUDENABLE
  [18:16] WLSDIO_DATA1_MUXMODE rw — Functional multiplexing selection for pad wlsdio_data1
    0=SEL_WLSDIO_DATA1 (Select wlsdio_data1); 1=SEL_MCSPI4_SOMI (Select mcspi4_somi); 7=SEL_SAFE_MODE_CORE161 (Select safe_mode_core161); 6=SEL_GPIO5_131 (Select gpio5_131)
  [15] WLSDIO_DATA0_WAKEUPEVENT ro — Pad_x wake-up event status latched in the IO
    values as CONTROL_CORE_PAD0_I2C3_SDA_PAD1_GPIO8_233.GPIO8_233_WAKEUPEVENT
  [14] WLSDIO_DATA0_WAKEUPENABLE rw — Input pad wake-up enable
    values as CONTROL_CORE_PAD0_I2C3_SDA_PAD1_GPIO8_233.GPIO8_233_WAKEUPENABLE
  [8] WLSDIO_DATA0_INPUTENABLE rw — Input enable value for pad wlsdio_data0
    values as CONTROL_CORE_PAD0_I2C3_SDA_PAD1_GPIO8_233.GPIO8_233_INPUTENABLE
  [5] WLSDIO_DATA0_PWRDOWN rw — Power Down setting for pad wlsdio_data0
    values as CONTROL_CORE_PAD0_I2C3_SDA_PAD1_GPIO8_233.GPIO8_233_PWRDOWN
  [4] WLSDIO_DATA0_PULLTYPESELECT rw — Pull-Up/Down selection for pad wlsdio_data0
    0=Pull-Down selected; 1=Pull-Up selected
  [3] WLSDIO_DATA0_PULLUDENABLE rw — Pull-Up/Down enable for pad wlsdio_data0
    values as CONTROL_CORE_PAD0_I2C3_SDA_PAD1_GPIO8_233.GPIO8_233_PULLUDENABLE
  [2:0] WLSDIO_DATA0_MUXMODE rw — Functional multiplexing selection for pad wlsdio_data0
    0=SEL_WLSDIO_DATA0 (Select wlsdio_data0); 1=SEL_MCSPI4_SIMO (Select mcspi4_simo); 7=SEL_SAFE_MODE_CORE160 (Select safe_mode_core160); 6=SEL_GPIO5_130 (Select gpio5_130)
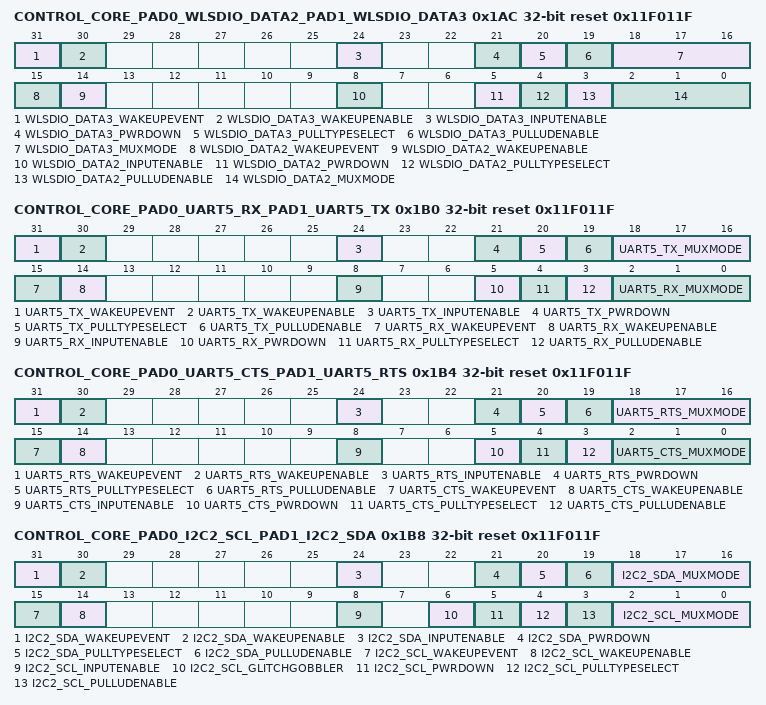
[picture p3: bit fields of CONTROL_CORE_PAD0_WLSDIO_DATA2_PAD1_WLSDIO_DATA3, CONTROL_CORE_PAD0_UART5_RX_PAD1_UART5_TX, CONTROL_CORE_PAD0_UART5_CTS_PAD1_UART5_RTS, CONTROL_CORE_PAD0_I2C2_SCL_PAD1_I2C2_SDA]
0x1AC CONTROL_CORE_PAD0_WLSDIO_DATA2_PAD1_WLSDIO_DATA3 reset 0x11F011F — Register control for Pads wlsdio_data2 and wlsdio_data3 Access conditions. Read: unrestricted, Write: unrestricted
  [31] WLSDIO_DATA3_WAKEUPEVENT ro — Pad_x wake-up event status latched in the IO
    values as CONTROL_CORE_PAD0_I2C3_SDA_PAD1_GPIO8_233.GPIO8_233_WAKEUPEVENT
  [30] WLSDIO_DATA3_WAKEUPENABLE rw — Input pad wake-up enable
    values as CONTROL_CORE_PAD0_I2C3_SDA_PAD1_GPIO8_233.GPIO8_233_WAKEUPENABLE
  [24] WLSDIO_DATA3_INPUTENABLE rw — Input enable value for pad wlsdio_data3
    values as CONTROL_CORE_PAD0_I2C3_SDA_PAD1_GPIO8_233.GPIO8_233_INPUTENABLE
  [21] WLSDIO_DATA3_PWRDOWN rw — Power Down setting for pad wlsdio_data3
    values as CONTROL_CORE_PAD0_I2C3_SDA_PAD1_GPIO8_233.GPIO8_233_PWRDOWN
  [20] WLSDIO_DATA3_PULLTYPESELECT rw — Pull-Up/Down selection for pad wlsdio_data3
    0=Pull-Down selected; 1=Pull-Up selected
  [19] WLSDIO_DATA3_PULLUDENABLE rw — Pull-Up/Down enable for pad wlsdio_data3
    values as CONTROL_CORE_PAD0_I2C3_SDA_PAD1_GPIO8_233.GPIO8_233_PULLUDENABLE
  [18:16] WLSDIO_DATA3_MUXMODE rw — Functional multiplexing selection for pad wlsdio_data3
    0=SEL_WLSDIO_DATA3 (Select wlsdio_data3); 7=SEL_SAFE_MODE_CORE163 (Select safe_mode_core163); 6=SEL_GPIO5_133 (Select gpio5_133)
  [15] WLSDIO_DATA2_WAKEUPEVENT ro — Pad_x wake-up event status latched in the IO
    values as CONTROL_CORE_PAD0_I2C3_SDA_PAD1_GPIO8_233.GPIO8_233_WAKEUPEVENT
  [14] WLSDIO_DATA2_WAKEUPENABLE rw — Input pad wake-up enable
    values as CONTROL_CORE_PAD0_I2C3_SDA_PAD1_GPIO8_233.GPIO8_233_WAKEUPENABLE
  [8] WLSDIO_DATA2_INPUTENABLE rw — Input enable value for pad wlsdio_data2
    values as CONTROL_CORE_PAD0_I2C3_SDA_PAD1_GPIO8_233.GPIO8_233_INPUTENABLE
  [5] WLSDIO_DATA2_PWRDOWN rw — Power Down setting for pad wlsdio_data2
    values as CONTROL_CORE_PAD0_I2C3_SDA_PAD1_GPIO8_233.GPIO8_233_PWRDOWN
  [4] WLSDIO_DATA2_PULLTYPESELECT rw — Pull-Up/Down selection for pad wlsdio_data2
    0=Pull-Down selected; 1=Pull-Up selected
  [3] WLSDIO_DATA2_PULLUDENABLE rw — Pull-Up/Down enable for pad wlsdio_data2
    values as CONTROL_CORE_PAD0_I2C3_SDA_PAD1_GPIO8_233.GPIO8_233_PULLUDENABLE
  [2:0] WLSDIO_DATA2_MUXMODE rw — Functional multiplexing selection for pad wlsdio_data2
    0=SEL_WLSDIO_DATA2 (Select wlsdio_data2); 1=SEL_MCSPI4_CS0 (Select mcspi4_cs0); 7=SEL_SAFE_MODE_CORE162 (Select safe_mode_core162); 6=SEL_GPIO5_132 (Select gpio5_132)
0x1B0 CONTROL_CORE_PAD0_UART5_RX_PAD1_UART5_TX reset 0x11F011F — Register control for Pads uart5_rx and uart5_tx Access conditions. Read: unrestricted, Write: unrestricted
  [31] UART5_TX_WAKEUPEVENT ro — Pad_x wake-up event status latched in the IO
    values as CONTROL_CORE_PAD0_I2C3_SDA_PAD1_GPIO8_233.GPIO8_233_WAKEUPEVENT
  [30] UART5_TX_WAKEUPENABLE rw — Input pad wake-up enable
    values as CONTROL_CORE_PAD0_I2C3_SDA_PAD1_GPIO8_233.GPIO8_233_WAKEUPENABLE
  [24] UART5_TX_INPUTENABLE rw — Input enable value for pad uart5_tx
    values as CONTROL_CORE_PAD0_I2C3_SDA_PAD1_GPIO8_233.GPIO8_233_INPUTENABLE
  [21] UART5_TX_PWRDOWN rw — Power Down setting for pad uart5_tx
    values as CONTROL_CORE_PAD0_I2C3_SDA_PAD1_GPIO8_233.GPIO8_233_PWRDOWN
  [20] UART5_TX_PULLTYPESELECT rw — Pull-Up/Down selection for pad uart5_tx
    0=Pull-Down selected; 1=Pull-Up selected
  [19] UART5_TX_PULLUDENABLE rw — Pull-Up/Down enable for pad uart5_tx
    values as CONTROL_CORE_PAD0_I2C3_SDA_PAD1_GPIO8_233.GPIO8_233_PULLUDENABLE
  [18:16] UART5_TX_MUXMODE rw — Functional multiplexing selection for pad uart5_tx
    0=SEL_UART5_TX (Select uart5_tx); 6=SEL_GPIO5_135 (Select gpio5_135); 4=SEL_SDIO4_DATA2 (Select sdio4_data2); 7=SEL_SAFE_MODE_CORE165 (Select safe_mode_core165); 5=SEL_HW_DBG29 (Select hw_dbg29)
  [15] UART5_RX_WAKEUPEVENT ro — Pad_x wake-up event status latched in the IO
    values as CONTROL_CORE_PAD0_I2C3_SDA_PAD1_GPIO8_233.GPIO8_233_WAKEUPEVENT
  [14] UART5_RX_WAKEUPENABLE rw — Input pad wake-up enable
    values as CONTROL_CORE_PAD0_I2C3_SDA_PAD1_GPIO8_233.GPIO8_233_WAKEUPENABLE
  [8] UART5_RX_INPUTENABLE rw — Input enable value for pad uart5_rx
    values as CONTROL_CORE_PAD0_I2C3_SDA_PAD1_GPIO8_233.GPIO8_233_INPUTENABLE
  [5] UART5_RX_PWRDOWN rw — Power Down setting for pad uart5_rx
    values as CONTROL_CORE_PAD0_I2C3_SDA_PAD1_GPIO8_233.GPIO8_233_PWRDOWN
  [4] UART5_RX_PULLTYPESELECT rw — Pull-Up/Down selection for pad uart5_rx
    0=Pull-Down selected; 1=Pull-Up selected
  [3] UART5_RX_PULLUDENABLE rw — Pull-Up/Down enable for pad uart5_rx
    values as CONTROL_CORE_PAD0_I2C3_SDA_PAD1_GPIO8_233.GPIO8_233_PULLUDENABLE
  [2:0] UART5_RX_MUXMODE rw — Functional multiplexing selection for pad uart5_rx
    0=SEL_UART5_RX (Select uart5_rx); 6=SEL_GPIO5_134 (Select gpio5_134); 4=SEL_SDIO4_DATA1 (Select sdio4_data1); 7=SEL_SAFE_MODE_CORE164 (Select safe_mode_core164); 5=SEL_HW_DBG28 (Select hw_dbg28)
0x1B4 CONTROL_CORE_PAD0_UART5_CTS_PAD1_UART5_RTS reset 0x11F011F — Register control for Pads uart5_cts and uart5_rts Access conditions. Read: unrestricted, Write: unrestricted
  [31] UART5_RTS_WAKEUPEVENT ro — Pad_x wake-up event status latched in the IO
    values as CONTROL_CORE_PAD0_I2C3_SDA_PAD1_GPIO8_233.GPIO8_233_WAKEUPEVENT
  [30] UART5_RTS_WAKEUPENABLE rw — Input pad wake-up enable
    values as CONTROL_CORE_PAD0_I2C3_SDA_PAD1_GPIO8_233.GPIO8_233_WAKEUPENABLE
  [24] UART5_RTS_INPUTENABLE rw — Input enable value for pad uart5_rts
    values as CONTROL_CORE_PAD0_I2C3_SDA_PAD1_GPIO8_233.GPIO8_233_INPUTENABLE
  [21] UART5_RTS_PWRDOWN rw — Power Down setting for pad uart5_rts
    values as CONTROL_CORE_PAD0_I2C3_SDA_PAD1_GPIO8_233.GPIO8_233_PWRDOWN
  [20] UART5_RTS_PULLTYPESELECT rw — Pull-Up/Down selection for pad uart5_rts
    0=Pull-Down selected; 1=Pull-Up selected
  [19] UART5_RTS_PULLUDENABLE rw — Pull-Up/Down enable for pad uart5_rts
    values as CONTROL_CORE_PAD0_I2C3_SDA_PAD1_GPIO8_233.GPIO8_233_PULLUDENABLE
  [18:16] UART5_RTS_MUXMODE rw — Functional multiplexing selection for pad uart5_rts
    0=SEL_UART5_RTS (Select uart5_rts); 6=SEL_GPIO5_137 (Select gpio5_137); 4=SEL_SDIO4_DATA3 (Select sdio4_data3); 7=SEL_SAFE_MODE_CORE167 (Select safe_mode_core167); 5=SEL_HW_DBG31 (Select hw_dbg31)
  [15] UART5_CTS_WAKEUPEVENT ro — Pad_x wake-up event status latched in the IO
    values as CONTROL_CORE_PAD0_I2C3_SDA_PAD1_GPIO8_233.GPIO8_233_WAKEUPEVENT
  [14] UART5_CTS_WAKEUPENABLE rw — Input pad wake-up enable
    values as CONTROL_CORE_PAD0_I2C3_SDA_PAD1_GPIO8_233.GPIO8_233_WAKEUPENABLE
  [8] UART5_CTS_INPUTENABLE rw — Input enable value for pad uart5_cts
    values as CONTROL_CORE_PAD0_I2C3_SDA_PAD1_GPIO8_233.GPIO8_233_INPUTENABLE
  [5] UART5_CTS_PWRDOWN rw — Power Down setting for pad uart5_cts
    values as CONTROL_CORE_PAD0_I2C3_SDA_PAD1_GPIO8_233.GPIO8_233_PWRDOWN
  [4] UART5_CTS_PULLTYPESELECT rw — Pull-Up/Down selection for pad uart5_cts
    0=Pull-Down selected; 1=Pull-Up selected
  [3] UART5_CTS_PULLUDENABLE rw — Pull-Up/Down enable for pad uart5_cts
    values as CONTROL_CORE_PAD0_I2C3_SDA_PAD1_GPIO8_233.GPIO8_233_PULLUDENABLE
  [2:0] UART5_CTS_MUXMODE rw — Functional multiplexing selection for pad uart5_cts
    0=SEL_UART5_CTS (Select uart5_cts); 6=SEL_GPIO5_136 (Select gpio5_136); 4=SEL_SDIO4_DATA0 (Select sdio4_data0); 7=SEL_SAFE_MODE_CORE166 (Select safe_mode_core166); 5=SEL_HW_DBG30 (Select hw_dbg30)
0x1B8 CONTROL_CORE_PAD0_I2C2_SCL_PAD1_I2C2_SDA reset 0x11F011F — Register control for Pads i2c2_scl and i2c2_sda Access conditions. Read: unrestricted, Write: unrestricted
  [31] I2C2_SDA_WAKEUPEVENT ro — Pad_x wake-up event status latched in the IO
    values as CONTROL_CORE_PAD0_I2C3_SDA_PAD1_GPIO8_233.GPIO8_233_WAKEUPEVENT
  [30] I2C2_SDA_WAKEUPENABLE rw — Input pad wake-up enable
    values as CONTROL_CORE_PAD0_I2C3_SDA_PAD1_GPIO8_233.GPIO8_233_WAKEUPENABLE
  [24] I2C2_SDA_INPUTENABLE rw — Input enable value for pad i2c2_sda
    values as CONTROL_CORE_PAD0_I2C3_SDA_PAD1_GPIO8_233.GPIO8_233_INPUTENABLE
  [21] I2C2_SDA_PWRDOWN rw — Power Down setting for pad i2c2_sda
    values as CONTROL_CORE_PAD0_I2C3_SDA_PAD1_GPIO8_233.GPIO8_233_PWRDOWN
  [20] I2C2_SDA_PULLTYPESELECT rw — Pull-Up/Down selection for pad i2c2_sda
    0=Pull-Down selected; 1=Pull-Up selected
  [19] I2C2_SDA_PULLUDENABLE rw — Pull-Up/Down enable for pad i2c2_sda
    values as CONTROL_CORE_PAD0_I2C3_SDA_PAD1_GPIO8_233.GPIO8_233_PULLUDENABLE
  [18:16] I2C2_SDA_MUXMODE rw — Functional multiplexing selection for pad i2c2_sda
    0=SEL_I2C2_SDA (Select i2c2_sda); 7=SEL_SAFE_MODE_CORE169 (Select safe_mode_core169); 6=SEL_GPIO5_139 (Select gpio5_139)
  [15] I2C2_SCL_WAKEUPEVENT ro — Pad_x wake-up event status latched in the IO
    values as CONTROL_CORE_PAD0_I2C3_SDA_PAD1_GPIO8_233.GPIO8_233_WAKEUPEVENT
  [14] I2C2_SCL_WAKEUPENABLE rw — Input pad wake-up enable
    values as CONTROL_CORE_PAD0_I2C3_SDA_PAD1_GPIO8_233.GPIO8_233_WAKEUPENABLE
  [8] I2C2_SCL_INPUTENABLE rw — Input enable value for pad i2c2_scl
    values as CONTROL_CORE_PAD0_I2C3_SDA_PAD1_GPIO8_233.GPIO8_233_INPUTENABLE
  [6] I2C2_SCL_GLITCHGOBBLER rw — Glitch Gobbler setting for pad i2c2_scl
    values as CONTROL_CORE_PAD0_ABEDMIC_DIN3_PAD1_ABEDMIC_CLK1.ABEDMIC_CLK1_GLITCHGOBBLER
  [5] I2C2_SCL_PWRDOWN rw — Power Down setting for pad i2c2_scl
    values as CONTROL_CORE_PAD0_I2C3_SDA_PAD1_GPIO8_233.GPIO8_233_PWRDOWN
  [4] I2C2_SCL_PULLTYPESELECT rw — Pull-Up/Down selection for pad i2c2_scl
    0=Pull-Down selected; 1=Pull-Up selected
  [3] I2C2_SCL_PULLUDENABLE rw — Pull-Up/Down enable for pad i2c2_scl
    values as CONTROL_CORE_PAD0_I2C3_SDA_PAD1_GPIO8_233.GPIO8_233_PULLUDENABLE
  [2:0] I2C2_SCL_MUXMODE rw — Functional multiplexing selection for pad i2c2_scl
    0=SEL_I2C2_SCL (Select i2c2_scl); 7=SEL_SAFE_MODE_CORE168 (Select safe_mode_core168); 6=SEL_GPIO5_138 (Select gpio5_138)
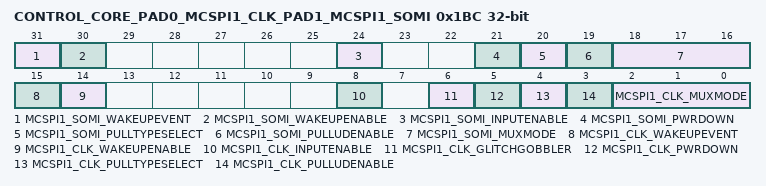
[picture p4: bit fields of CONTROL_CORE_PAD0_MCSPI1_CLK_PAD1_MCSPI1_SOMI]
0x1BC CONTROL_CORE_PAD0_MCSPI1_CLK_PAD1_MCSPI1_SOMI — Register control for Pads mcspi1_clk and mcspi1_somi Access conditions. Read: unrestricted, Write: unrestricted
  [31] MCSPI1_SOMI_WAKEUPEVENT ro — Pad_x wake-up event status latched in the IO
    values as CONTROL_CORE_PAD0_I2C3_SDA_PAD1_GPIO8_233.GPIO8_233_WAKEUPEVENT
  [30] MCSPI1_SOMI_WAKEUPENABLE rw — Input pad wake-up enable
    values as CONTROL_CORE_PAD0_I2C3_SDA_PAD1_GPIO8_233.GPIO8_233_WAKEUPENABLE
  [24] MCSPI1_SOMI_INPUTENABLE rw — Input enable value for pad mcspi1_somi
    values as CONTROL_CORE_PAD0_I2C3_SDA_PAD1_GPIO8_233.GPIO8_233_INPUTENABLE
  [21] MCSPI1_SOMI_PWRDOWN rw — Power Down setting for pad mcspi1_somi
    values as CONTROL_CORE_PAD0_I2C3_SDA_PAD1_GPIO8_233.GPIO8_233_PWRDOWN
  [20] MCSPI1_SOMI_PULLTYPESELECT rw — Pull-Up/Down selection for pad mcspi1_somi
    0=Pull-Down selected; 1=Pull-Up selected
  [19] MCSPI1_SOMI_PULLUDENABLE rw — Pull-Up/Down enable for pad mcspi1_somi
    values as CONTROL_CORE_PAD0_I2C3_SDA_PAD1_GPIO8_233.GPIO8_233_PULLUDENABLE
  [18:16] MCSPI1_SOMI_MUXMODE rw — Functional multiplexing selection for pad mcspi1_somi
    0=SEL_MCSPI1_SOMI (Select mcspi1_somi); 6=SEL_GPIO5_141 (Select gpio5_141); 7=SEL_SAFE_MODE_CORE171 (Select safe_mode_core171); 5=SEL_USBD0_ULPIPHY_NXT (Select usbd0_ulpiphy_nxt)
  [15] MCSPI1_CLK_WAKEUPEVENT ro — Pad_x wake-up event status latched in the IO
    values as CONTROL_CORE_PAD0_I2C3_SDA_PAD1_GPIO8_233.GPIO8_233_WAKEUPEVENT
  [14] MCSPI1_CLK_WAKEUPENABLE rw — Input pad wake-up enable
    values as CONTROL_CORE_PAD0_I2C3_SDA_PAD1_GPIO8_233.GPIO8_233_WAKEUPENABLE
  [8] MCSPI1_CLK_INPUTENABLE rw — Input enable value for pad mcspi1_clk
    values as CONTROL_CORE_PAD0_I2C3_SDA_PAD1_GPIO8_233.GPIO8_233_INPUTENABLE
  [6] MCSPI1_CLK_GLITCHGOBBLER rw — Glitch Gobbler setting for pad mcspi1_clk
    values as CONTROL_CORE_PAD0_ABEDMIC_DIN3_PAD1_ABEDMIC_CLK1.ABEDMIC_CLK1_GLITCHGOBBLER
  [5] MCSPI1_CLK_PWRDOWN rw — Power Down setting for pad mcspi1_clk
    values as CONTROL_CORE_PAD0_I2C3_SDA_PAD1_GPIO8_233.GPIO8_233_PWRDOWN
  [4] MCSPI1_CLK_PULLTYPESELECT rw — Pull-Up/Down selection for pad mcspi1_clk
    0=Pull-Down selected; 1=Pull-Up selected
  [3] MCSPI1_CLK_PULLUDENABLE rw — Pull-Up/Down enable for pad mcspi1_clk
    values as CONTROL_CORE_PAD0_I2C3_SDA_PAD1_GPIO8_233.GPIO8_233_PULLUDENABLE
  [2:0] MCSPI1_CLK_MUXMODE rw — Functional multiplexing selection for pad mcspi1_clk
    0=SEL_MCSPI1_CLK (Select mcspi1_clk); 6=SEL_GPIO5_140 (Select gpio5_140); 7=SEL_SAFE_MODE_CORE170 (Select safe_mode_core170); 5=SEL_USBD0_ULPIPHY_CLK (Select usbd0_ulpiphy_clk)
